AUTOSAR XML (schema 4-2-2)
package /ComponentTypes
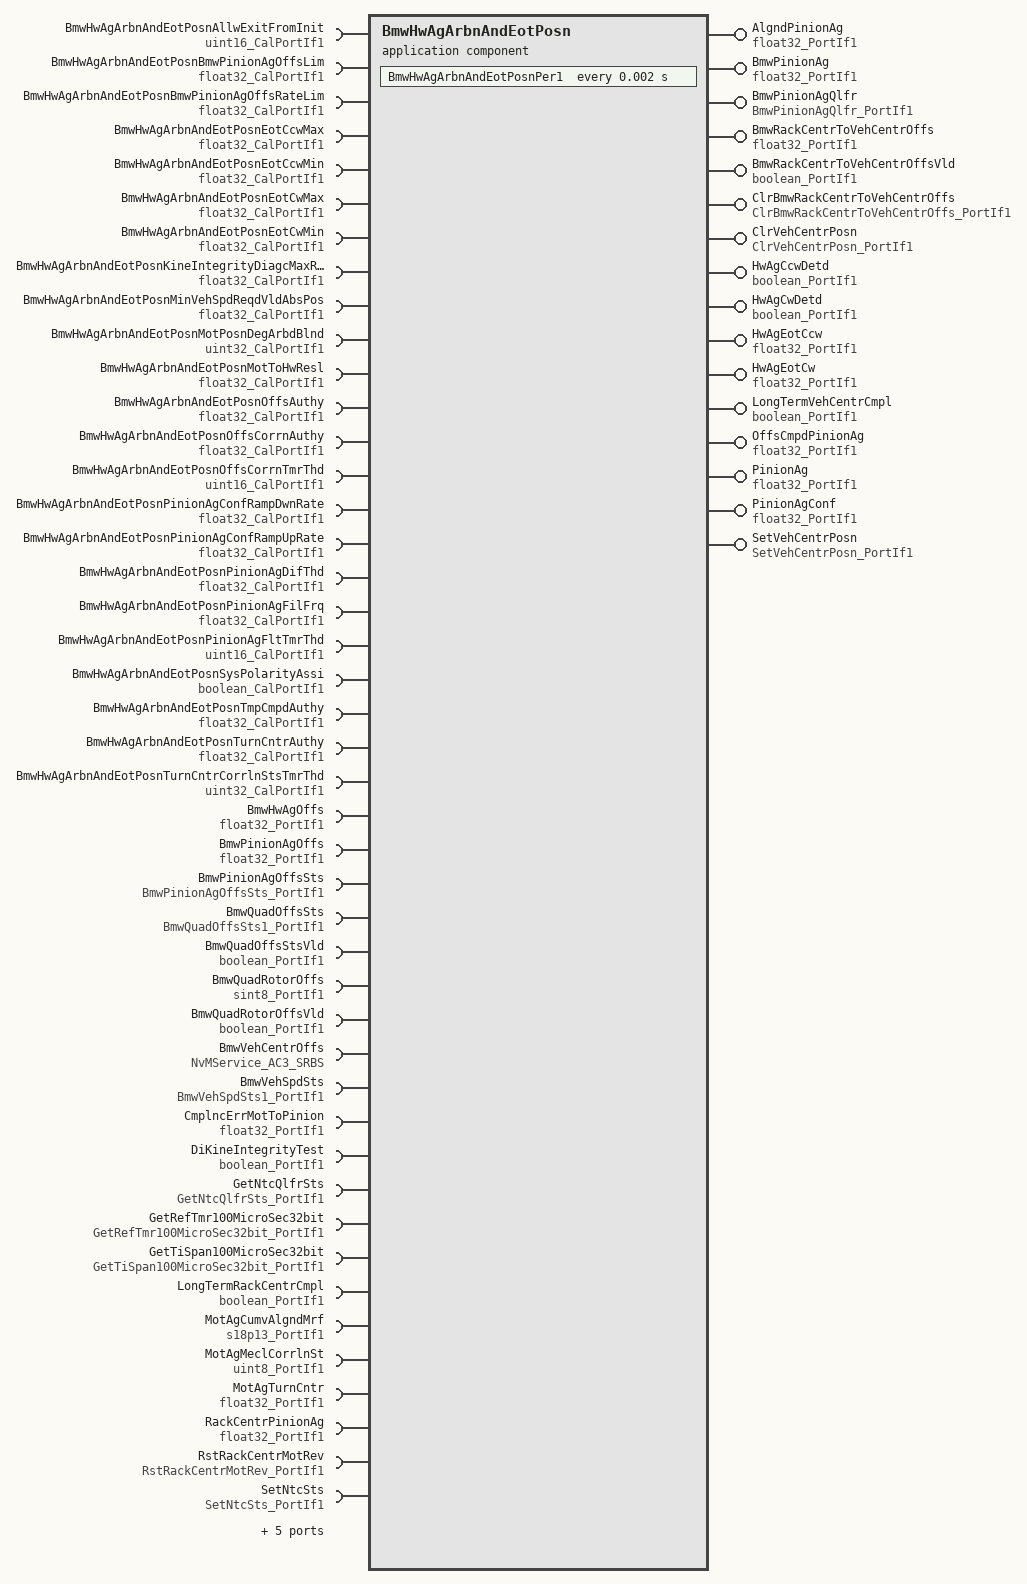
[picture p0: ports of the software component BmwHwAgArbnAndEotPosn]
  application sw component type BmwHwAgArbnAndEotPosn
    16 x provide port:
      AlgndPinionAg: nonqueued-sender-com-spec{data-element=Val, init-value=0}, provided-interface=float32_PortIf1
      BmwPinionAg: nonqueued-sender-com-spec{data-element=Val, init-value=0}, provided-interface=float32_PortIf1
      BmwPinionAgQlfr: nonqueued-sender-com-spec{data-element=Val, init-value=14}, provided-interface=BmwPinionAgQlfr_PortIf1
      BmwRackCentrToVehCentrOffs: nonqueued-sender-com-spec{data-element=Val, init-value=0}, provided-interface=float32_PortIf1
      BmwRackCentrToVehCentrOffsVld: nonqueued-sender-com-spec{data-element=Logl, init-value=0}, provided-interface=boolean_PortIf1
      ClrBmwRackCentrToVehCentrOffs: server-com-spec{operation=Oper, queue-length=1}, provided-interface=ClrBmwRackCentrToVehCentrOffs_PortIf1
      ClrVehCentrPosn: server-com-spec{operation=Oper, queue-length=1}, provided-interface=ClrVehCentrPosn_PortIf1
      HwAgCcwDetd: nonqueued-sender-com-spec{data-element=Logl, init-value=0}, provided-interface=boolean_PortIf1
      HwAgCwDetd: nonqueued-sender-com-spec{data-element=Logl, init-value=0}, provided-interface=boolean_PortIf1
      HwAgEotCcw: nonqueued-sender-com-spec{data-element=Val, init-value=-360}, provided-interface=float32_PortIf1
      HwAgEotCw: nonqueued-sender-com-spec{data-element=Val, init-value=360}, provided-interface=float32_PortIf1
      LongTermVehCentrCmpl: nonqueued-sender-com-spec{data-element=Logl, init-value=0}, provided-interface=boolean_PortIf1
      OffsCmpdPinionAg: nonqueued-sender-com-spec{data-element=Val, init-value=0}, provided-interface=float32_PortIf1
      PinionAg: nonqueued-sender-com-spec{data-element=Val, init-value=0}, provided-interface=float32_PortIf1
      PinionAgConf: nonqueued-sender-com-spec{data-element=Val, init-value=0}, provided-interface=float32_PortIf1
      SetVehCentrPosn: server-com-spec{operation=Oper, queue-length=1}, provided-interface=SetVehCentrPosn_PortIf1
    49 x require port:
      BmwHwAgArbnAndEotPosnAllwExitFromInit: parameter-require-com-spec{init-value=200, parameter=Val}, required-interface=uint16_CalPortIf1
      BmwHwAgArbnAndEotPosnBmwPinionAgOffsLim: parameter-require-com-spec{init-value=0, parameter=Val}, required-interface=float32_CalPortIf1
      BmwHwAgArbnAndEotPosnBmwPinionAgOffsRateLim: parameter-require-com-spec{init-value=50, parameter=Val}, required-interface=float32_CalPortIf1
      BmwHwAgArbnAndEotPosnEotCcwMax: parameter-require-com-spec{init-value=-360, parameter=Val}, required-interface=float32_CalPortIf1
      BmwHwAgArbnAndEotPosnEotCcwMin: parameter-require-com-spec{init-value=-900, parameter=Val}, required-interface=float32_CalPortIf1
      BmwHwAgArbnAndEotPosnEotCwMax: parameter-require-com-spec{init-value=900, parameter=Val}, required-interface=float32_CalPortIf1
      BmwHwAgArbnAndEotPosnEotCwMin: parameter-require-com-spec{init-value=360, parameter=Val}, required-interface=float32_CalPortIf1
      BmwHwAgArbnAndEotPosnKineIntegrityDiagcMaxRackLim: parameter-require-com-spec{init-value=2100, parameter=Val}, required-interface=float32_CalPortIf1
      BmwHwAgArbnAndEotPosnMinVehSpdReqdVldAbsPos: parameter-require-com-spec{init-value=18, parameter=Val}, required-interface=float32_CalPortIf1
      BmwHwAgArbnAndEotPosnMotPosnDegArbdBlnd: parameter-require-com-spec{init-value=200, parameter=Val}, required-interface=uint32_CalPortIf1
      BmwHwAgArbnAndEotPosnMotToHwResl: parameter-require-com-spec{init-value=1, parameter=Val}, required-interface=float32_CalPortIf1
      BmwHwAgArbnAndEotPosnOffsAuthy: parameter-require-com-spec{init-value=1, parameter=Val}, required-interface=float32_CalPortIf1
      BmwHwAgArbnAndEotPosnOffsCorrnAuthy: parameter-require-com-spec{init-value=0.8, parameter=Val}, required-interface=float32_CalPortIf1
      BmwHwAgArbnAndEotPosnOffsCorrnTmrThd: parameter-require-com-spec{init-value=50, parameter=Val}, required-interface=uint16_CalPortIf1
      BmwHwAgArbnAndEotPosnPinionAgConfRampDwnRate: parameter-require-com-spec{init-value=1, parameter=Val}, required-interface=float32_CalPortIf1
      BmwHwAgArbnAndEotPosnPinionAgConfRampUpRate: parameter-require-com-spec{init-value=0.2, parameter=Val}, required-interface=float32_CalPortIf1
      BmwHwAgArbnAndEotPosnPinionAgDifThd: parameter-require-com-spec{init-value=7.5, parameter=Val}, required-interface=float32_CalPortIf1
      BmwHwAgArbnAndEotPosnPinionAgFilFrq: parameter-require-com-spec{init-value=10, parameter=Val}, required-interface=float32_CalPortIf1
      BmwHwAgArbnAndEotPosnPinionAgFltTmrThd: parameter-require-com-spec{init-value=20, parameter=Val}, required-interface=uint16_CalPortIf1
      BmwHwAgArbnAndEotPosnSysPolarityAssi: parameter-require-com-spec{init-value=1, parameter=Logl}, required-interface=boolean_CalPortIf1
      BmwHwAgArbnAndEotPosnTmpCmpdAuthy: parameter-require-com-spec{init-value=0.6, parameter=Val}, required-interface=float32_CalPortIf1
      BmwHwAgArbnAndEotPosnTurnCntrAuthy: parameter-require-com-spec{init-value=1, parameter=Val}, required-interface=float32_CalPortIf1
      BmwHwAgArbnAndEotPosnTurnCntrCorrlnStsTmrThd: parameter-require-com-spec{init-value=50, parameter=Val}, required-interface=uint32_CalPortIf1
      BmwHwAgOffs: nonqueued-receiver-com-spec{data-element=Val, filter=data-filter-type=ALWAYS, init-value=0}, required-interface=float32_PortIf1
      BmwPinionAgOffs: nonqueued-receiver-com-spec{data-element=Val, filter=data-filter-type=ALWAYS, init-value=0}, required-interface=float32_PortIf1
      BmwPinionAgOffsSts: nonqueued-receiver-com-spec{data-element=Val, filter=data-filter-type=ALWAYS, init-value=4}, required-interface=BmwPinionAgOffsSts_PortIf1
      BmwQuadOffsSts: nonqueued-receiver-com-spec{data-element=Val, filter=data-filter-type=ALWAYS, init-value=15}, required-interface=BmwQuadOffsSts1_PortIf1
      BmwQuadOffsStsVld: nonqueued-receiver-com-spec{data-element=Logl, filter=data-filter-type=ALWAYS, init-value=0}, required-interface=boolean_PortIf1
      BmwQuadRotorOffs: nonqueued-receiver-com-spec{data-element=Val, filter=data-filter-type=ALWAYS, init-value=0}, required-interface=sint8_PortIf1
      BmwQuadRotorOffsVld: nonqueued-receiver-com-spec{data-element=Logl, filter=data-filter-type=ALWAYS, init-value=0}, required-interface=boolean_PortIf1
      BmwVehCentrOffs: required-com-specs=[EraseBlock, GetErrorStatus, InvalidateNvBlock, ReadBlock, SetRamBlockStatus, WriteBlock], required-interface=NvMService_AC3_SRBS
      BmwVehSpdSts: nonqueued-receiver-com-spec{data-element=Val, filter=data-filter-type=ALWAYS, init-value=15}, required-interface=BmwVehSpdSts1_PortIf1
      CmplncErrMotToPinion: nonqueued-receiver-com-spec{data-element=Val, filter=data-filter-type=ALWAYS, init-value=0}, required-interface=float32_PortIf1
      DiKineIntegrityTest: nonqueued-receiver-com-spec{data-element=Logl, filter=data-filter-type=ALWAYS, init-value=0}, required-interface=boolean_PortIf1
      GetNtcQlfrSts: client-com-spec=Oper, required-interface=GetNtcQlfrSts_PortIf1
      GetRefTmr100MicroSec32bit: client-com-spec=Oper, required-interface=GetRefTmr100MicroSec32bit_PortIf1
      GetTiSpan100MicroSec32bit: client-com-spec=Oper, required-interface=GetTiSpan100MicroSec32bit_PortIf1
      LongTermRackCentrCmpl: nonqueued-receiver-com-spec{data-element=Logl, filter=data-filter-type=ALWAYS, init-value=0}, required-interface=boolean_PortIf1
      MotAgCumvAlgndMrf: nonqueued-receiver-com-spec{data-element=Val, filter=data-filter-type=ALWAYS, init-value=0}, required-interface=s18p13_PortIf1
      MotAgMeclCorrlnSt: nonqueued-receiver-com-spec{data-element=Val, filter=data-filter-type=ALWAYS, init-value=3}, required-interface=uint8_PortIf1
      MotAgTurnCntr: nonqueued-receiver-com-spec{data-element=Val, filter=data-filter-type=ALWAYS, init-value=0}, required-interface=float32_PortIf1
      RackCentrPinionAg: nonqueued-receiver-com-spec{data-element=Val, filter=data-filter-type=ALWAYS, init-value=0}, required-interface=float32_PortIf1
      RstRackCentrMotRev: client-com-spec=Oper, required-interface=RstRackCentrMotRev_PortIf1
      SetNtcSts: client-com-spec=Oper, required-interface=SetNtcSts_PortIf1
      SysGlbPrmSysKineRat: parameter-require-com-spec{init-value=22, parameter=Val}, required-interface=float32_CalPortIf1
      TotRackTrvl: nonqueued-receiver-com-spec{data-element=Val, filter=data-filter-type=ALWAYS, init-value=0}, required-interface=float32_PortIf1
      TurnCntrCorrlnSts: nonqueued-receiver-com-spec{data-element=Val, filter=data-filter-type=ALWAYS, init-value=3}, required-interface=uint8_PortIf1
      VehSpd: nonqueued-receiver-com-spec{data-element=Val, filter=data-filter-type=ALWAYS, init-value=0}, required-interface=float32_PortIf1
      VehSpdVld: nonqueued-receiver-com-spec{data-element=Logl, filter=data-filter-type=ALWAYS, init-value=0}, required-interface=boolean_PortIf1
    behavior BmwHwAgArbnAndEotPosn_InternalBehavior
      ar-typed-per-instance-memorys:
        36 x data, all with sw-calibration-access=READ-ONLY:
          AllwExitFromInitTi: type=uint32  # Allow Exit From Initialization Time
          BmwPinionAgOffsRateLim: type=float32
          BmwRackCentrToVehCentrOffsSts: type=BmwRackToVehCentrOffsSts1  # BMW Rack Center To Vehicle Center Offset Status
          BmwVehCentrOffs: type=BmwVehCentrOffsRec1  # BMW Vehicle Center Offsets
          ClrNotCmplPinionAgFlg: type=boolean  # Clear Not Complete Pinion Angle Flag
          CurrAlgndPinionAg: type=float32  # Current Aligned Pinion Angle
          CurrDftPinionAgFltPrsnt: type=boolean  # Current Default Pinion Angle Fault Present
          dBmwHwAgArbnAndEotPosnBmwMotAgSelnSt: type=uint8
          DynStabyCtrlCdn: type=boolean
          FirstLoopIndcr: type=uint8  # This PIM is only needed for the purpose of catching first cycle of the periodic where BmwMotAgSelnSt stays in INIT. If it is equal to 0, then first loop is going, every other value is useless.
          IniTurnCntrCorrlnSts: type=uint8
          KineIntegrityFlt: type=boolean  # Kinematic Integrity Fault Flag
          LpFilActvd: type=boolean
          MotPosnDegArbdBlndFac: type=boolean
          MotPosnDegArbdBlndTi: type=uint32
          OffsCorrnRefTi: type=uint32  # Offset Correction Reference Time
          PinionAgConfRampStVari: type=float32  # Pinion Angle Confidence Ramp First State Variable
          PinionAgFilStVari: type=FilLpRec1  # Pinion Angle Filter State Variable
          PinionAgFltRefTi: type=uint32  # Pinion Angle Fault Reference Time
          PrevAllwCorrn: type=boolean  # Previous Allow Correction
          PrevBmwMotAgSelnSt: type=BmwMotAgSelnSt1  # This is the state which we came from to the current state.
          PrevBmwOffsAuthy: type=float32  # Previous BMW Offset Authority
          PrevBmwOffsAuthyFlg: type=boolean  # Previous BMW Offset Authority Flag
          PrevIgnCycBmwMotAgSelnSt: type=uint8
          PrevIgnCycNtc8CSts: type=uint8
          PrevIgnCycNtc8ESts: type=uint8
          PrevIgnCycTurnCntrCorrlnSts: type=uint8
          PrevLoopBmwMotAgSelnSt: type=BmwMotAgSelnSt1  # This is the state which was calculated 2 ms ago, in the previous loop of the periodic function.
          PrevLoopBmwQuadOffsSts: type=BmwQuadOffsSts1
          PrevLoopPinionAg: type=float32
          PrevPinionAgConf: type=float32  # Previous Pinion Angle Confidence
          SetBmwRackCentrToVehCentrOffsTrig: type=boolean  # Set BMW Rack Center To Vehicle Center Offset Trigger
          SigInvldTranTrig: type=boolean  # 0 - DftHwPosn plus UntrimPinionAg AND !TurnsCntrVld, 1 - UntrimPinionAg AND TurnsCntrVld
          TurnCntrCorrlnStsTmrTrig: type=boolean
          TurnCntrValTi: type=uint32
          VehCentrCmpl: type=boolean  # Vehicle Center Complete Flag
      init event BmwHwAgArbnAndEotPosn_InitEvent: start-on-event=BmwHwAgArbnAndEotPosnInit1
      timing event TMT_BmwHwAgArbnAndEotPosnPer1: start-on-event=BmwHwAgArbnAndEotPosnPer1, period=0.002
      operation invoked event OIT_ClrBmwRackCentrToVehCentrOffs_Oper_ClrBmwRackCentrToVehCentrOffs_Oper: start-on-event=ClrBmwRackCentrToVehCentrOffs_Oper, operation=ClrBmwRackCentrToVehCentrOffs.Oper
      operation invoked event OIT_ClrVehCentrPosn_Oper_ClrVehCentrPosn_Oper: start-on-event=ClrVehCentrPosn_Oper, operation=ClrVehCentrPosn.Oper
      operation invoked event OIT_SetVehCentrPosn_Oper_SetVehCentrPosn_Oper: start-on-event=SetVehCentrPosn_Oper, operation=SetVehCentrPosn.Oper
      port-api-options:
        enable-take-address=false, error-handling=NO-TRANSFORMER-ERROR-HANDLING, indirect-api=false, port=AlgndPinionAg
        enable-take-address=false, error-handling=NO-TRANSFORMER-ERROR-HANDLING, indirect-api=false, port=BmwHwAgArbnAndEotPosnAllwExitFromInit
        enable-take-address=false, error-handling=NO-TRANSFORMER-ERROR-HANDLING, indirect-api=false, port=BmwHwAgArbnAndEotPosnBmwPinionAgOffsLim
        enable-take-address=false, error-handling=NO-TRANSFORMER-ERROR-HANDLING, indirect-api=false, port=BmwHwAgArbnAndEotPosnBmwPinionAgOffsRateLim
        enable-take-address=false, error-handling=NO-TRANSFORMER-ERROR-HANDLING, indirect-api=false, port=BmwHwAgArbnAndEotPosnEotCcwMax
        enable-take-address=false, error-handling=NO-TRANSFORMER-ERROR-HANDLING, indirect-api=false, port=BmwHwAgArbnAndEotPosnEotCcwMin
        enable-take-address=false, error-handling=NO-TRANSFORMER-ERROR-HANDLING, indirect-api=false, port=BmwHwAgArbnAndEotPosnEotCwMax
        enable-take-address=false, error-handling=NO-TRANSFORMER-ERROR-HANDLING, indirect-api=false, port=BmwHwAgArbnAndEotPosnEotCwMin
        enable-take-address=false, error-handling=NO-TRANSFORMER-ERROR-HANDLING, indirect-api=false, port=BmwHwAgArbnAndEotPosnKineIntegrityDiagcMaxRackLim
        enable-take-address=false, error-handling=NO-TRANSFORMER-ERROR-HANDLING, indirect-api=false, port=BmwHwAgArbnAndEotPosnMinVehSpdReqdVldAbsPos
        enable-take-address=false, error-handling=NO-TRANSFORMER-ERROR-HANDLING, indirect-api=false, port=BmwHwAgArbnAndEotPosnMotPosnDegArbdBlnd
        enable-take-address=false, error-handling=NO-TRANSFORMER-ERROR-HANDLING, indirect-api=false, port=BmwHwAgArbnAndEotPosnMotToHwResl
        enable-take-address=false, error-handling=NO-TRANSFORMER-ERROR-HANDLING, indirect-api=false, port=BmwHwAgArbnAndEotPosnOffsAuthy
        enable-take-address=false, error-handling=NO-TRANSFORMER-ERROR-HANDLING, indirect-api=false, port=BmwHwAgArbnAndEotPosnOffsCorrnAuthy
        enable-take-address=false, error-handling=NO-TRANSFORMER-ERROR-HANDLING, indirect-api=false, port=BmwHwAgArbnAndEotPosnOffsCorrnTmrThd
        enable-take-address=false, error-handling=NO-TRANSFORMER-ERROR-HANDLING, indirect-api=false, port=BmwHwAgArbnAndEotPosnPinionAgConfRampDwnRate
        enable-take-address=false, error-handling=NO-TRANSFORMER-ERROR-HANDLING, indirect-api=false, port=BmwHwAgArbnAndEotPosnPinionAgConfRampUpRate
        enable-take-address=false, error-handling=NO-TRANSFORMER-ERROR-HANDLING, indirect-api=false, port=BmwHwAgArbnAndEotPosnPinionAgDifThd
        enable-take-address=false, error-handling=NO-TRANSFORMER-ERROR-HANDLING, indirect-api=false, port=BmwHwAgArbnAndEotPosnPinionAgFilFrq
        enable-take-address=false, error-handling=NO-TRANSFORMER-ERROR-HANDLING, indirect-api=false, port=BmwHwAgArbnAndEotPosnPinionAgFltTmrThd
        enable-take-address=false, error-handling=NO-TRANSFORMER-ERROR-HANDLING, indirect-api=false, port=BmwHwAgArbnAndEotPosnSysPolarityAssi
        enable-take-address=false, error-handling=NO-TRANSFORMER-ERROR-HANDLING, indirect-api=false, port=BmwHwAgArbnAndEotPosnTmpCmpdAuthy
        enable-take-address=false, error-handling=NO-TRANSFORMER-ERROR-HANDLING, indirect-api=false, port=BmwHwAgArbnAndEotPosnTurnCntrAuthy
        enable-take-address=false, error-handling=NO-TRANSFORMER-ERROR-HANDLING, indirect-api=false, port=BmwHwAgArbnAndEotPosnTurnCntrCorrlnStsTmrThd
        enable-take-address=false, error-handling=NO-TRANSFORMER-ERROR-HANDLING, indirect-api=false, port=BmwHwAgOffs
        enable-take-address=false, error-handling=NO-TRANSFORMER-ERROR-HANDLING, indirect-api=false, port=BmwPinionAg
        enable-take-address=false, error-handling=NO-TRANSFORMER-ERROR-HANDLING, indirect-api=false, port=BmwPinionAgOffs
        enable-take-address=false, error-handling=NO-TRANSFORMER-ERROR-HANDLING, indirect-api=false, port=BmwPinionAgOffsSts
        enable-take-address=false, error-handling=NO-TRANSFORMER-ERROR-HANDLING, indirect-api=false, port=BmwPinionAgQlfr
        enable-take-address=false, error-handling=NO-TRANSFORMER-ERROR-HANDLING, indirect-api=false, port=BmwQuadOffsSts
        enable-take-address=false, error-handling=NO-TRANSFORMER-ERROR-HANDLING, indirect-api=false, port=BmwQuadOffsStsVld
        enable-take-address=false, error-handling=NO-TRANSFORMER-ERROR-HANDLING, indirect-api=false, port=BmwQuadRotorOffs
        enable-take-address=false, error-handling=NO-TRANSFORMER-ERROR-HANDLING, indirect-api=false, port=BmwQuadRotorOffsVld
        enable-take-address=false, error-handling=NO-TRANSFORMER-ERROR-HANDLING, indirect-api=false, port=BmwRackCentrToVehCentrOffs
        enable-take-address=false, error-handling=NO-TRANSFORMER-ERROR-HANDLING, indirect-api=false, port=BmwRackCentrToVehCentrOffsVld
        enable-take-address=false, error-handling=NO-TRANSFORMER-ERROR-HANDLING, indirect-api=false, port=BmwVehCentrOffs
        enable-take-address=false, error-handling=NO-TRANSFORMER-ERROR-HANDLING, indirect-api=false, port=BmwVehSpdSts
        enable-take-address=false, error-handling=NO-TRANSFORMER-ERROR-HANDLING, indirect-api=false, port=ClrBmwRackCentrToVehCentrOffs
        enable-take-address=false, error-handling=NO-TRANSFORMER-ERROR-HANDLING, indirect-api=false, port=ClrVehCentrPosn
        enable-take-address=false, error-handling=NO-TRANSFORMER-ERROR-HANDLING, indirect-api=false, port=CmplncErrMotToPinion
        enable-take-address=false, error-handling=NO-TRANSFORMER-ERROR-HANDLING, indirect-api=false, port=DiKineIntegrityTest
        enable-take-address=false, error-handling=NO-TRANSFORMER-ERROR-HANDLING, indirect-api=false, port=GetNtcQlfrSts
        enable-take-address=false, error-handling=NO-TRANSFORMER-ERROR-HANDLING, indirect-api=false, port=GetRefTmr100MicroSec32bit
        enable-take-address=false, error-handling=NO-TRANSFORMER-ERROR-HANDLING, indirect-api=false, port=GetTiSpan100MicroSec32bit
        enable-take-address=false, error-handling=NO-TRANSFORMER-ERROR-HANDLING, indirect-api=false, port=HwAgCcwDetd
        enable-take-address=false, error-handling=NO-TRANSFORMER-ERROR-HANDLING, indirect-api=false, port=HwAgCwDetd
        enable-take-address=false, error-handling=NO-TRANSFORMER-ERROR-HANDLING, indirect-api=false, port=HwAgEotCcw
        enable-take-address=false, error-handling=NO-TRANSFORMER-ERROR-HANDLING, indirect-api=false, port=HwAgEotCw
        enable-take-address=false, error-handling=NO-TRANSFORMER-ERROR-HANDLING, indirect-api=false, port=LongTermRackCentrCmpl
        enable-take-address=false, error-handling=NO-TRANSFORMER-ERROR-HANDLING, indirect-api=false, port=LongTermVehCentrCmpl
        enable-take-address=false, error-handling=NO-TRANSFORMER-ERROR-HANDLING, indirect-api=false, port=MotAgCumvAlgndMrf
        enable-take-address=false, error-handling=NO-TRANSFORMER-ERROR-HANDLING, indirect-api=false, port=MotAgMeclCorrlnSt
        enable-take-address=false, error-handling=NO-TRANSFORMER-ERROR-HANDLING, indirect-api=false, port=MotAgTurnCntr
        enable-take-address=false, error-handling=NO-TRANSFORMER-ERROR-HANDLING, indirect-api=false, port=OffsCmpdPinionAg
        enable-take-address=false, error-handling=NO-TRANSFORMER-ERROR-HANDLING, indirect-api=false, port=PinionAg
        enable-take-address=false, error-handling=NO-TRANSFORMER-ERROR-HANDLING, indirect-api=false, port=PinionAgConf
        enable-take-address=false, error-handling=NO-TRANSFORMER-ERROR-HANDLING, indirect-api=false, port=RackCentrPinionAg
        enable-take-address=false, error-handling=NO-TRANSFORMER-ERROR-HANDLING, indirect-api=false, port=RstRackCentrMotRev
        enable-take-address=false, error-handling=NO-TRANSFORMER-ERROR-HANDLING, indirect-api=false, port=SetNtcSts
        enable-take-address=false, error-handling=NO-TRANSFORMER-ERROR-HANDLING, indirect-api=false, port=SetVehCentrPosn
        enable-take-address=false, error-handling=NO-TRANSFORMER-ERROR-HANDLING, indirect-api=false, port=SysGlbPrmSysKineRat
        enable-take-address=false, error-handling=NO-TRANSFORMER-ERROR-HANDLING, indirect-api=false, port=TotRackTrvl
        enable-take-address=false, error-handling=NO-TRANSFORMER-ERROR-HANDLING, indirect-api=false, port=TurnCntrCorrlnSts
        enable-take-address=false, error-handling=NO-TRANSFORMER-ERROR-HANDLING, indirect-api=false, port=VehSpd
        enable-take-address=false, error-handling=NO-TRANSFORMER-ERROR-HANDLING, indirect-api=false, port=VehSpdVld
      5 x runnable:
        BmwHwAgArbnAndEotPosnInit1  # Function initialization
          sync call SC_NvMService_AC3_SRBS_GetErrorStatus: operation=BmwVehCentrOffs.GetErrorStatus, timeout=0
          sync call SC_NvMService_AC3_SRBS_SetRamBlockStatus: operation=BmwVehCentrOffs.SetRamBlockStatus, timeout=0
        BmwHwAgArbnAndEotPosnPer1  # Periodic functionality
          data-receive-point-by-arguments:
            19 x access:
              REC_BmwHwAgOffs_Val: accessed-variable=BmwHwAgOffs.Val
              REC_BmwPinionAgOffs_Val: accessed-variable=BmwPinionAgOffs.Val
              REC_BmwPinionAgOffsSts_Val: accessed-variable=BmwPinionAgOffsSts.Val
              REC_BmwQuadOffsSts_Val: accessed-variable=BmwQuadOffsSts.Val
              REC_BmwQuadOffsStsVld_Logl: accessed-variable=BmwQuadOffsStsVld.Logl
              REC_BmwQuadRotorOffs_Val_1: accessed-variable=BmwQuadRotorOffs.Val
              REC_BmwQuadRotorOffsVld_Logl: accessed-variable=BmwQuadRotorOffsVld.Logl
              REC_BmwVehSpdSts_Val: accessed-variable=BmwVehSpdSts.Val
              REC_CmplncErrMotToPinion_Val: accessed-variable=CmplncErrMotToPinion.Val
              REC_DiKineIntegrityTest_Logl: accessed-variable=DiKineIntegrityTest.Logl
              REC_LongTermRackCentrCmpl_Logl: accessed-variable=LongTermRackCentrCmpl.Logl
              REC_MotAgCumvAlgndMrf_Val: accessed-variable=MotAgCumvAlgndMrf.Val
              REC_MotAgMeclCorrlnSt_Val: accessed-variable=MotAgMeclCorrlnSt.Val
              REC_MotAgTurnCntr_Val: accessed-variable=MotAgTurnCntr.Val
              REC_RackCentrPinionAg_Val: accessed-variable=RackCentrPinionAg.Val
              REC_TotRackTrvl_Val: accessed-variable=TotRackTrvl.Val
              REC_TurnCntrCorrlnSts_Val: accessed-variable=TurnCntrCorrlnSts.Val
              REC_VehSpd_Val: accessed-variable=VehSpd.Val
              REC_VehSpdVld_Logl: accessed-variable=VehSpdVld.Logl
          data-send-points:
            13 x access:
              SEND_AlgndPinionAg_Val: accessed-variable=AlgndPinionAg.Val
              SEND_BmwPinionAg_Val: accessed-variable=BmwPinionAg.Val
              SEND_BmwPinionAgQlfr_Val: accessed-variable=BmwPinionAgQlfr.Val
              SEND_BmwRackCentrToVehCentrOffs_Val: accessed-variable=BmwRackCentrToVehCentrOffs.Val
              SEND_BmwRackCentrToVehCentrOffsVld_Logl: accessed-variable=BmwRackCentrToVehCentrOffsVld.Logl
              SEND_HwAgCcwDetd_Logl: accessed-variable=HwAgCcwDetd.Logl
              SEND_HwAgCwDetd_Logl: accessed-variable=HwAgCwDetd.Logl
              SEND_HwAgEotCcw_Val: accessed-variable=HwAgEotCcw.Val
              SEND_HwAgEotCw_Val: accessed-variable=HwAgEotCw.Val
              SEND_LongTermVehCentrCmpl_Logl: accessed-variable=LongTermVehCentrCmpl.Logl
              SEND_OffsCmpdPinionAg_Val: accessed-variable=OffsCmpdPinionAg.Val
              SEND_PinionAg_Val: accessed-variable=PinionAg.Val
              SEND_PinionAgConf_Val: accessed-variable=PinionAgConf.Val
          5 x sync call, all with timeout=0:
            SC_GetNtcQlfrSts_Oper: operation=GetNtcQlfrSts.Oper
            SC_GetRefTmr100MicroSec32bit_Oper: operation=GetRefTmr100MicroSec32bit.Oper
            SC_GetTiSpan100MicroSec32bit_Oper: operation=GetTiSpan100MicroSec32bit.Oper
            SC_RstRackCentrMotRev_Oper: operation=RstRackCentrMotRev.Oper
            SC_SetNtcSts_Oper: operation=SetNtcSts.Oper
        ClrBmwRackCentrToVehCentrOffs_Oper
        ClrVehCentrPosn_Oper
        SetVehCentrPosn_Oper
      swc service dependency NvmBmwVehCentrOffs: assigned-datas=role-based-data-assignment={role=ramBlock, used-data-element=BmwVehCentrOffs}, assigned-ports=role-based-port-assignment={port-prototype=BmwVehCentrOffs, role=NvMService_AC3_SRBS}
        service-needs:
          nv block needs NvmBmwVehCentrOffs: n-data-sets=0, ram-block-status-control=API, readonly=false, reliability=ERROR-DETECTION, resistant-to-changed-sw=true, restore-at-start=true, store-at-shutdown=true, write-only-once=false, writing-frequency=0, writing-priority=LOW
  swc implementation BmwHwAgArbnAndEotPosn_Implementation: behavior=BmwHwAgArbnAndEotPosn_InternalBehavior
    code-descriptors:
      code Default: artifact-descriptors=autosar-engineering-object={short-label=Default, category=SWSRC}
